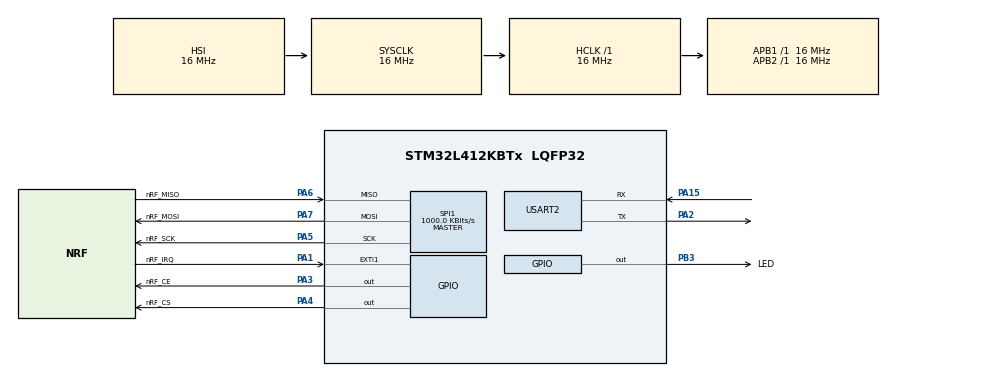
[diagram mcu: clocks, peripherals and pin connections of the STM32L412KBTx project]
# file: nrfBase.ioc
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FREERTOS.Tasks01=defaultTask,24,128,StartDefaultTask,Default,NULL,Dynamic,NULL,NULL
FREERTOS.configUSE_NEWLIB_REENTRANT=1
Mcu.Family=STM32L4
Mcu.Name=STM32L412KBTx
Mcu.Package=LQFP32
NVIC.EXTI1_IRQn=true\:8\:0\:true\:false\:true\:true\:true\:true\:true
NVIC.PriorityGroup=NVIC_PRIORITYGROUP_4
NVIC.TIM6_IRQn=true\:15\:0\:false\:false\:true\:false\:false\:true\:true
NVIC.TimeBase=TIM6_IRQn
NVIC.TimeBaseIP=TIM6
NVIC.USART2_IRQn=true\:5\:0\:false\:false\:true\:true\:true\:true\:true
PA1.GPIO_Label=nRF_IRQ
PA1.GPIO_ModeDefaultEXTI=GPIO_MODE_IT_FALLING
PA1.GPIO_PuPd=GPIO_PULLUP
PA1.Signal=GPXTI1
PA13\ (JTMS/SWDIO).Mode=Serial_Wire
PA13\ (JTMS/SWDIO).Signal=SYS_JTMS-SWDIO
PA14\ (JTCK/SWCLK).Mode=Serial_Wire
PA14\ (JTCK/SWCLK).Signal=SYS_JTCK-SWCLK
PA15\ (JTDI).Mode=Asynchronous
PA15\ (JTDI).Signal=USART2_RX
PA2.Mode=Asynchronous
PA2.Signal=USART2_TX
PA3.GPIO_Label=nRF_CE
PA3.GPIO_Speed=GPIO_SPEED_FREQ_HIGH
PA3.Signal=GPIO_Output
PA4.GPIO_Label=nRF_CS
PA4.GPIO_Speed=GPIO_SPEED_FREQ_HIGH
PA4.Signal=GPIO_Output
PA5.GPIO_Label=nRF_SCK
PA5.Mode=Full_Duplex_Master
PA5.Signal=SPI1_SCK
PA6.GPIO_Label=nRF_MISO
PA6.Mode=Full_Duplex_Master
PA6.Signal=SPI1_MISO
PA7.GPIO_Label=nRF_MOSI
PA7.Mode=Full_Duplex_Master
PA7.Signal=SPI1_MOSI
PB3\ (JTDO/TRACESWO).GPIO_Label=LED
PB3\ (JTDO/TRACESWO).GPIO_Speed=GPIO_SPEED_FREQ_VERY_HIGH
PB3\ (JTDO/TRACESWO).Signal=GPIO_Output
ProjectManager.HeapSize=0x200
ProjectManager.StackSize=0x400
ProjectManager.TargetToolchain=STM32CubeIDE
RCC.ADCFreq_Value=16000000
RCC.AHBFreq_Value=16000000
RCC.APB1Freq_Value=16000000
RCC.APB1TimFreq_Value=16000000
RCC.APB2Freq_Value=16000000
RCC.APB2TimFreq_Value=16000000
RCC.CortexFreq_Value=16000000
RCC.HCLKFreq_Value=16000000
RCC.HSE_VALUE=8000000
RCC.HSI48_VALUE=48000000
RCC.HSI_VALUE=16000000
RCC.LSE_VALUE=32768
RCC.MSI_VALUE=4000000
RCC.PLLSourceVirtual=RCC_PLLSOURCE_HSI
RCC.SYSCLKFreq_VALUE=16000000
RCC.SYSCLKSource=RCC_SYSCLKSOURCE_HSI
RCC.USBFreq_Value=4000000
RCC.VCOOutputFreq_Value=128000000
SPI1.BaudRatePrescaler=SPI_BAUDRATEPRESCALER_16
SPI1.CalculateBaudRate=1000.0 KBits/s
SPI1.DataSize=SPI_DATASIZE_8BIT
SPI1.Direction=SPI_DIRECTION_2LINES
SPI1.Mode=SPI_MODE_MASTER
SPI1.VirtualType=VM_MASTER
USART2.VirtualMode-Asynchronous=VM_ASYNC
VP_FREERTOS_VS_CMSIS_V2.Mode=CMSIS_V2
VP_SYS_VS_tim6.Mode=TIM6
board=custom

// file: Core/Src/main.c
/* USER CODE BEGIN Header */
/**
  ******************************************************************************
  * @file           : main.c
  * @brief          : Main program body
  ******************************************************************************
  * @attention
  *
  * Copyright (c) 2026 STMicroelectronics.
  * All rights reserved.
  *
  * This software is licensed under terms that can be found in the LICENSE file
  * in the root directory of this software component.
  * If no LICENSE file comes with this software, it is provided AS-IS.
  *
  ******************************************************************************
  */
/* USER CODE END Header */
#include "main.h"
#include "cmsis_os.h"
#include "spi.h"
#include "usart.h"
#include "gpio.h"

/* USER CODE BEGIN Includes */
#include "nrf24.h"
/* USER CODE END Includes */

void SystemClock_Config(void);
void MX_FREERTOS_Init(void);

int main(void)
{

  /* MCU Configuration--------------------------------------------------------*/

  /* Reset of all peripherals, Initializes the Flash interface and the Systick. */
  HAL_Init();

  /* Configure the system clock */
  SystemClock_Config();

  /* Initialize all configured peripherals */
  MX_GPIO_Init();
  MX_SPI1_Init();
  MX_USART2_UART_Init();
  /* USER CODE BEGIN 2 */

  uart_init();
  uart_send_string("nrf42 base");
  uart_send_string("\n+ file: ");
  uart_send_string(__FILE__);
  uart_send_string("\n+ compile date: ");
  uart_send_string(__DATE__);
  uart_send_string(", ");
  uart_send_string(__TIME__);
  uart_send_string("\nstart Listening for packets:\n");
  nrf24_init(nRF24_ROLE_CENTRAL);
  nrf24_open();
  /* USER CODE END 2 */

  /* Init scheduler */
  osKernelInitialize();  /* Call init function for freertos objects (in cmsis_os2.c) */
  MX_FREERTOS_Init();

  /* Start scheduler */
  osKernelStart();

  /* We should never get here as control is now taken by the scheduler */

  /* Infinite loop */
  while (1)
  {

  }
}

void SystemClock_Config(void)
{
  RCC_OscInitTypeDef RCC_OscInitStruct = {0};
  RCC_ClkInitTypeDef RCC_ClkInitStruct = {0};

  /** Configure the main internal regulator output voltage
  */
  if (HAL_PWREx_ControlVoltageScaling(PWR_REGULATOR_VOLTAGE_SCALE1) != HAL_OK)
  {
    Error_Handler();
  }

  /** Initializes the RCC Oscillators according to the specified parameters
  * in the RCC_OscInitTypeDef structure.
  */
  RCC_OscInitStruct.OscillatorType = RCC_OSCILLATORTYPE_HSI;
  RCC_OscInitStruct.HSIState = RCC_HSI_ON;
  RCC_OscInitStruct.HSICalibrationValue = RCC_HSICALIBRATION_DEFAULT;
  RCC_OscInitStruct.PLL.PLLState = RCC_PLL_NONE;
  if (HAL_RCC_OscConfig(&RCC_OscInitStruct) != HAL_OK)
  {
    Error_Handler();
  }

  /** Initializes the CPU, AHB and APB buses clocks
  */
  RCC_ClkInitStruct.ClockType = RCC_CLOCKTYPE_HCLK|RCC_CLOCKTYPE_SYSCLK
                              |RCC_CLOCKTYPE_PCLK1|RCC_CLOCKTYPE_PCLK2;
  RCC_ClkInitStruct.SYSCLKSource = RCC_SYSCLKSOURCE_HSI;
  RCC_ClkInitStruct.AHBCLKDivider = RCC_SYSCLK_DIV1;
  RCC_ClkInitStruct.APB1CLKDivider = RCC_HCLK_DIV1;
  RCC_ClkInitStruct.APB2CLKDivider = RCC_HCLK_DIV1;

  if (HAL_RCC_ClockConfig(&RCC_ClkInitStruct, FLASH_LATENCY_0) != HAL_OK)
  {
    Error_Handler();
  }
}

void HAL_TIM_PeriodElapsedCallback(TIM_HandleTypeDef *htim)
{
  if (htim->Instance == TIM6)
  {
    HAL_IncTick();
  }
}

void Error_Handler(void)
{
  __disable_irq();
  while (1)
  {
  }
}

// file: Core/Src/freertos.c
/* USER CODE BEGIN Header */
/**
  ******************************************************************************
  * File Name          : freertos.c
  * Description        : Code for freertos applications
  ******************************************************************************
  * @attention
  *
  * Copyright (c) 2026 STMicroelectronics.
  * All rights reserved.
  *
  * This software is licensed under terms that can be found in the LICENSE file
  * in the root directory of this software component.
  * If no LICENSE file comes with this software, it is provided AS-IS.
  *
  ******************************************************************************
  */
/* USER CODE END Header */

#include "FreeRTOS.h"
#include "task.h"
#include "main.h"
#include "cmsis_os.h"

/* Definitions for defaultTask */
osThreadId_t defaultTaskHandle;
const osThreadAttr_t defaultTask_attributes = {
  .name = "defaultTask",
  .stack_size = 128 * 4,
  .priority = (osPriority_t) osPriorityNormal,
};

void StartDefaultTask(void *argument);

void MX_FREERTOS_Init(void); /* (MISRA C 2004 rule 8.1) */

void MX_FREERTOS_Init(void) {

  /* Create the thread(s) */
  /* creation of defaultTask */
  defaultTaskHandle = osThreadNew(StartDefaultTask, NULL, &defaultTask_attributes);

}

void StartDefaultTask(void *argument)
{
  /* USER CODE BEGIN StartDefaultTask */
  /* Infinite loop */
  for(;;)
  {
    osDelay(1000);
  }
  /* USER CODE END StartDefaultTask */
}
